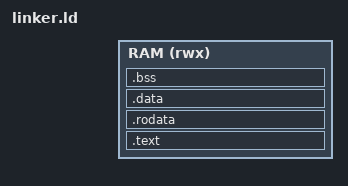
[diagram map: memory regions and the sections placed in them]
OUTPUT_ARCH(riscv)
ENTRY(_start)

MEMORY
{
    RAM (rwx) : ORIGIN = EMBENCH_RAM_BASE, LENGTH = EMBENCH_RAM_SIZE
}

SECTIONS
{
    . = ORIGIN(RAM);

    .text : ALIGN(16)
    {
        KEEP(*(.text.start))
        *(.text .text.*)
    } > RAM

    .rodata : ALIGN(16)
    {
        *(.rodata .rodata.*)
        *(.srodata .srodata.*)
    } > RAM

    .data : ALIGN(16)
    {
        PROVIDE(__global_pointer$ = . + 0x800);
        *(.data .data.*)
        *(.sdata .sdata.*)
    } > RAM

    .bss (NOLOAD) : ALIGN(16)
    {
        __bss_start = .;
        *(.bss .bss.*)
        *(.sbss .sbss.*)
        *(COMMON)
        __bss_end = .;
    } > RAM

    . = ALIGN(16);
    __heap_start = .;
    __stack_top = ORIGIN(RAM) + LENGTH(RAM);
    __stack_bottom = __stack_top - 0x10000;

    /DISCARD/ :
    {
        *(.comment)
        *(.eh_frame .eh_frame.*)
    }
}

ASSERT(__heap_start < __stack_bottom, "Embench image does not fit in guest RAM")
